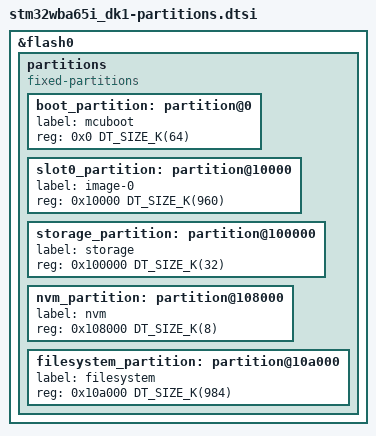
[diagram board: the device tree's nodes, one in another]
/* Partition layout for stm32wba65i_dk1: the flash memory map shared by the
 * bootloader and every application image. Generated by
 * tools/partition_layout.py; do not edit by hand -- re-run
 * `python3 tools/partition_layout.py --fix stm32wba65i_dk1` after changing
 * the upstream board geometry or tools/boards.toml.
 *
 * Board-specific overlay glue (delete-nodes, device enablement,
 * aliases/chosen) lives in dts/st/stm32wba65i_dk1.dtsi, which includes
 * this file.
 */

&flash0 {
	partitions {
		compatible = "fixed-partitions";
		#address-cells = <1>;
		#size-cells = <1>;

		boot_partition: partition@0 {
			label = "mcuboot";
			reg = <0x0 DT_SIZE_K(64)>;
		};

		slot0_partition: partition@10000 {
			label = "image-0";
			reg = <0x10000 DT_SIZE_K(960)>;
		};

		storage_partition: partition@100000 {
			label = "storage";
			reg = <0x100000 DT_SIZE_K(32)>;
		};

		nvm_partition: partition@108000 {
			label = "nvm";
			reg = <0x108000 DT_SIZE_K(8)>;
		};

		filesystem_partition: partition@10a000 {
			label = "filesystem";
			reg = <0x10a000 DT_SIZE_K(984)>;
		};
	};
};
